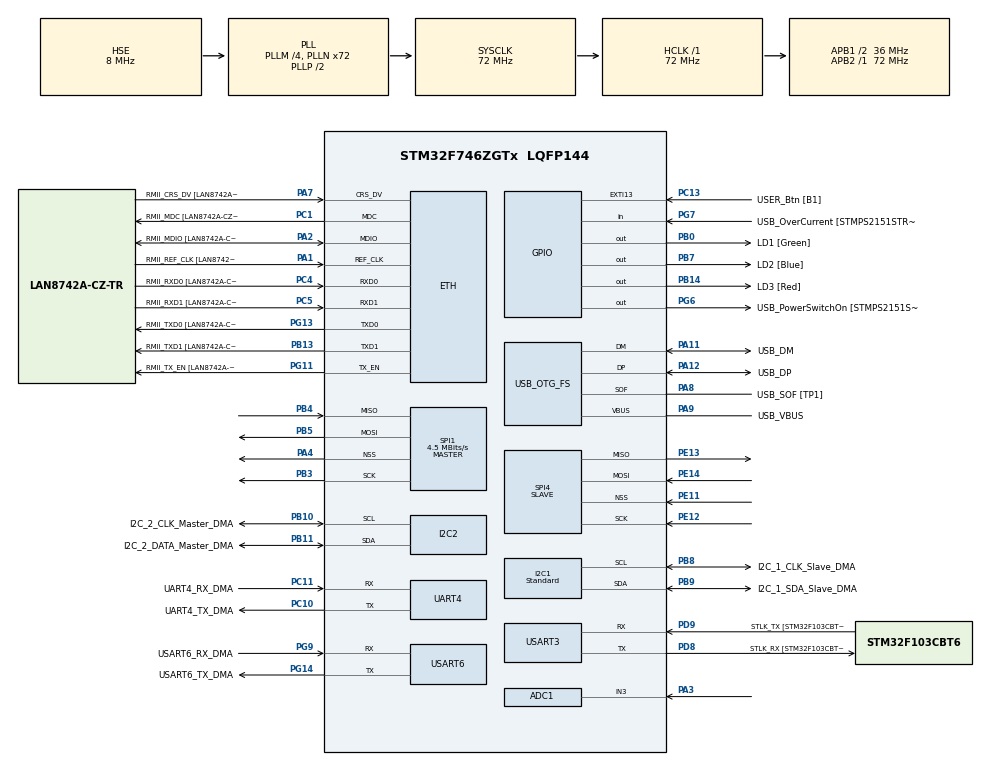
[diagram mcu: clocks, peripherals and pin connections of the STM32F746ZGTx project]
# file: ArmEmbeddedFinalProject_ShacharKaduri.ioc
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ADC1.Channel-0\#ChannelRegularConversion=ADC_CHANNEL_3
ADC1.ClockPrescaler=ADC_CLOCK_SYNC_PCLK_DIV8
ADC1.ContinuousConvMode=DISABLE
ADC1.DMAContinuousRequests=ENABLE
ADC1.InjNumberOfConversion=0
ADC1.NbrOfConversionFlag=1
ADC1.Rank-0\#ChannelRegularConversion=1
ADC1.SamplingTime-0\#ChannelRegularConversion=ADC_SAMPLETIME_84CYCLES
ADC1.master=1
Dma.ADC1.12.Direction=DMA_PERIPH_TO_MEMORY
Dma.ADC1.12.FIFOMode=DMA_FIFOMODE_DISABLE
Dma.ADC1.12.Instance=DMA2_Stream4
Dma.ADC1.12.MemDataAlignment=DMA_MDATAALIGN_HALFWORD
Dma.ADC1.12.MemInc=DMA_MINC_ENABLE
Dma.ADC1.12.Mode=DMA_CIRCULAR
Dma.ADC1.12.PeriphDataAlignment=DMA_PDATAALIGN_HALFWORD
Dma.ADC1.12.PeriphInc=DMA_PINC_DISABLE
Dma.ADC1.12.Priority=DMA_PRIORITY_LOW
Dma.I2C1_RX.6.Direction=DMA_PERIPH_TO_MEMORY
Dma.I2C1_RX.6.FIFOMode=DMA_FIFOMODE_DISABLE
Dma.I2C1_RX.6.Instance=DMA1_Stream5
Dma.I2C1_RX.6.MemDataAlignment=DMA_MDATAALIGN_BYTE
Dma.I2C1_RX.6.MemInc=DMA_MINC_ENABLE
Dma.I2C1_RX.6.Mode=DMA_NORMAL
Dma.I2C1_RX.6.PeriphDataAlignment=DMA_PDATAALIGN_BYTE
Dma.I2C1_RX.6.PeriphInc=DMA_PINC_DISABLE
Dma.I2C1_RX.6.Priority=DMA_PRIORITY_LOW
Dma.I2C1_TX.7.Direction=DMA_MEMORY_TO_PERIPH
Dma.I2C1_TX.7.FIFOMode=DMA_FIFOMODE_DISABLE
Dma.I2C1_TX.7.Instance=DMA1_Stream6
Dma.I2C1_TX.7.MemDataAlignment=DMA_MDATAALIGN_BYTE
Dma.I2C1_TX.7.MemInc=DMA_MINC_ENABLE
Dma.I2C1_TX.7.Mode=DMA_NORMAL
Dma.I2C1_TX.7.PeriphDataAlignment=DMA_PDATAALIGN_BYTE
Dma.I2C1_TX.7.PeriphInc=DMA_PINC_DISABLE
Dma.I2C1_TX.7.Priority=DMA_PRIORITY_LOW
Dma.I2C2_RX.4.Direction=DMA_PERIPH_TO_MEMORY
Dma.I2C2_RX.4.FIFOMode=DMA_FIFOMODE_DISABLE
Dma.I2C2_RX.4.Instance=DMA1_Stream3
Dma.I2C2_RX.4.MemDataAlignment=DMA_MDATAALIGN_BYTE
Dma.I2C2_RX.4.MemInc=DMA_MINC_ENABLE
Dma.I2C2_RX.4.Mode=DMA_NORMAL
Dma.I2C2_RX.4.PeriphDataAlignment=DMA_PDATAALIGN_BYTE
Dma.I2C2_RX.4.PeriphInc=DMA_PINC_DISABLE
Dma.I2C2_RX.4.Priority=DMA_PRIORITY_LOW
Dma.I2C2_TX.5.Direction=DMA_MEMORY_TO_PERIPH
Dma.I2C2_TX.5.FIFOMode=DMA_FIFOMODE_DISABLE
Dma.I2C2_TX.5.Instance=DMA1_Stream7
Dma.I2C2_TX.5.MemDataAlignment=DMA_MDATAALIGN_BYTE
Dma.I2C2_TX.5.MemInc=DMA_MINC_ENABLE
Dma.I2C2_TX.5.Mode=DMA_NORMAL
Dma.I2C2_TX.5.PeriphDataAlignment=DMA_PDATAALIGN_BYTE
Dma.I2C2_TX.5.PeriphInc=DMA_PINC_DISABLE
Dma.I2C2_TX.5.Priority=DMA_PRIORITY_LOW
Dma.Request0=UART4_RX
Dma.Request1=UART4_TX
Dma.Request10=SPI1_RX
Dma.Request11=SPI1_TX
Dma.Request12=ADC1
Dma.Request2=USART6_RX
Dma.Request3=USART6_TX
Dma.Request4=I2C2_RX
Dma.Request5=I2C2_TX
Dma.Request6=I2C1_RX
Dma.Request7=I2C1_TX
Dma.Request8=SPI4_RX
Dma.Request9=SPI4_TX
Dma.SPI1_RX.10.Direction=DMA_PERIPH_TO_MEMORY
Dma.SPI1_RX.10.FIFOMode=DMA_FIFOMODE_DISABLE
Dma.SPI1_RX.10.Instance=DMA2_Stream0
Dma.SPI1_RX.10.MemDataAlignment=DMA_MDATAALIGN_BYTE
Dma.SPI1_RX.10.MemInc=DMA_MINC_ENABLE
Dma.SPI1_RX.10.Mode=DMA_NORMAL
Dma.SPI1_RX.10.PeriphDataAlignment=DMA_PDATAALIGN_BYTE
Dma.SPI1_RX.10.PeriphInc=DMA_PINC_DISABLE
Dma.SPI1_RX.10.Priority=DMA_PRIORITY_LOW
Dma.SPI1_TX.11.Direction=DMA_MEMORY_TO_PERIPH
Dma.SPI1_TX.11.FIFOMode=DMA_FIFOMODE_DISABLE
Dma.SPI1_TX.11.Instance=DMA2_Stream5
Dma.SPI1_TX.11.MemDataAlignment=DMA_MDATAALIGN_BYTE
Dma.SPI1_TX.11.MemInc=DMA_MINC_ENABLE
Dma.SPI1_TX.11.Mode=DMA_NORMAL
Dma.SPI1_TX.11.PeriphDataAlignment=DMA_PDATAALIGN_BYTE
Dma.SPI1_TX.11.PeriphInc=DMA_PINC_DISABLE
Dma.SPI1_TX.11.Priority=DMA_PRIORITY_LOW
Dma.SPI4_RX.8.Direction=DMA_PERIPH_TO_MEMORY
Dma.SPI4_RX.8.FIFOMode=DMA_FIFOMODE_DISABLE
Dma.SPI4_RX.8.Instance=DMA2_Stream3
Dma.SPI4_RX.8.MemDataAlignment=DMA_MDATAALIGN_BYTE
Dma.SPI4_RX.8.MemInc=DMA_MINC_ENABLE
Dma.SPI4_RX.8.Mode=DMA_NORMAL
Dma.SPI4_RX.8.PeriphDataAlignment=DMA_PDATAALIGN_BYTE
Dma.SPI4_RX.8.PeriphInc=DMA_PINC_DISABLE
Dma.SPI4_RX.8.Priority=DMA_PRIORITY_LOW
Dma.SPI4_TX.9.Direction=DMA_MEMORY_TO_PERIPH
Dma.SPI4_TX.9.FIFOMode=DMA_FIFOMODE_DISABLE
Dma.SPI4_TX.9.Instance=DMA2_Stream1
Dma.SPI4_TX.9.MemDataAlignment=DMA_MDATAALIGN_BYTE
Dma.SPI4_TX.9.MemInc=DMA_MINC_ENABLE
Dma.SPI4_TX.9.Mode=DMA_NORMAL
Dma.SPI4_TX.9.PeriphDataAlignment=DMA_PDATAALIGN_BYTE
Dma.SPI4_TX.9.PeriphInc=DMA_PINC_DISABLE
Dma.SPI4_TX.9.Priority=DMA_PRIORITY_LOW
Dma.UART4_RX.0.Direction=DMA_PERIPH_TO_MEMORY
Dma.UART4_RX.0.FIFOMode=DMA_FIFOMODE_DISABLE
Dma.UART4_RX.0.Instance=DMA1_Stream2
Dma.UART4_RX.0.MemDataAlignment=DMA_MDATAALIGN_BYTE
Dma.UART4_RX.0.MemInc=DMA_MINC_ENABLE
Dma.UART4_RX.0.Mode=DMA_NORMAL
Dma.UART4_RX.0.PeriphDataAlignment=DMA_PDATAALIGN_BYTE
Dma.UART4_RX.0.PeriphInc=DMA_PINC_DISABLE
Dma.UART4_RX.0.Priority=DMA_PRIORITY_LOW
Dma.UART4_TX.1.Direction=DMA_MEMORY_TO_PERIPH
Dma.UART4_TX.1.FIFOMode=DMA_FIFOMODE_DISABLE
Dma.UART4_TX.1.Instance=DMA1_Stream4
Dma.UART4_TX.1.MemDataAlignment=DMA_MDATAALIGN_BYTE
Dma.UART4_TX.1.MemInc=DMA_MINC_ENABLE
Dma.UART4_TX.1.Mode=DMA_NORMAL
Dma.UART4_TX.1.PeriphDataAlignment=DMA_PDATAALIGN_BYTE
Dma.UART4_TX.1.PeriphInc=DMA_PINC_DISABLE
Dma.UART4_TX.1.Priority=DMA_PRIORITY_LOW
Dma.USART6_RX.2.Direction=DMA_PERIPH_TO_MEMORY
Dma.USART6_RX.2.FIFOMode=DMA_FIFOMODE_DISABLE
Dma.USART6_RX.2.Instance=DMA2_Stream2
Dma.USART6_RX.2.MemDataAlignment=DMA_MDATAALIGN_BYTE
Dma.USART6_RX.2.MemInc=DMA_MINC_ENABLE
Dma.USART6_RX.2.Mode=DMA_NORMAL
Dma.USART6_RX.2.PeriphDataAlignment=DMA_PDATAALIGN_BYTE
Dma.USART6_RX.2.PeriphInc=DMA_PINC_DISABLE
Dma.USART6_RX.2.Priority=DMA_PRIORITY_LOW
Dma.USART6_TX.3.Direction=DMA_MEMORY_TO_PERIPH
Dma.USART6_TX.3.FIFOMode=DMA_FIFOMODE_DISABLE
Dma.USART6_TX.3.Instance=DMA2_Stream6
Dma.USART6_TX.3.MemDataAlignment=DMA_MDATAALIGN_BYTE
Dma.USART6_TX.3.MemInc=DMA_MINC_ENABLE
Dma.USART6_TX.3.Mode=DMA_NORMAL
Dma.USART6_TX.3.PeriphDataAlignment=DMA_PDATAALIGN_BYTE
Dma.USART6_TX.3.PeriphInc=DMA_PINC_DISABLE
Dma.USART6_TX.3.Priority=DMA_PRIORITY_LOW
ETH.MediaInterface=HAL_ETH_RMII_MODE
ETH.PHY_Name=LAN8742A_PHY_ADDRESS
ETH.PHY_Value=0
ETH.PhyAddress=0
I2C1.AddressingMode=I2C_ADDRESSINGMODE_7BIT
I2C1.I2C_Speed_Mode=I2C_Standard
I2C1.OwnAddress=15
I2C1.Timing=0x10808DD3
I2C2.AddressingMode=I2C_ADDRESSINGMODE_7BIT
I2C2.Timing=0x10808DD3
LWIP.BSP.number=1
LWIP.IP_ADDRESS=192.168.001.002
LWIP.LWIP_DHCP=0
LWIP.NETMASK_ADDRESS=255.255.255.000
LWIP.Version=v2.1.2_Cube
LWIP0.BSP.STBoard=false
LWIP0.BSP.api=BSP_COMPONENT_DRIVER
LWIP0.BSP.component=LAN8742
LWIP0.BSP.instance=LAN8742
LWIP0.BSP.name=Driver_PHY
LWIP0.BSP.semaphore=S_LAN8742
LWIP0.BSP.solution=LAN8742
Mcu.Family=STM32F7
Mcu.Name=STM32F746ZGTx
Mcu.Package=LQFP144
NVIC.ADC_IRQn=true\:0\:0\:false\:false\:true\:true\:true\:true
NVIC.DMA1_Stream2_IRQn=true\:0\:0\:false\:false\:true\:false\:true\:true
NVIC.DMA1_Stream3_IRQn=true\:0\:0\:false\:false\:true\:false\:true\:true
NVIC.DMA1_Stream4_IRQn=true\:0\:0\:false\:false\:true\:false\:true\:true
NVIC.DMA1_Stream5_IRQn=true\:0\:0\:false\:false\:true\:false\:true\:true
NVIC.DMA1_Stream6_IRQn=true\:0\:0\:false\:false\:true\:false\:true\:true
NVIC.DMA1_Stream7_IRQn=true\:0\:0\:false\:false\:true\:false\:true\:true
NVIC.DMA2_Stream0_IRQn=true\:0\:0\:false\:false\:true\:false\:true\:true
NVIC.DMA2_Stream1_IRQn=true\:0\:0\:false\:false\:true\:false\:true\:true
NVIC.DMA2_Stream2_IRQn=true\:0\:0\:false\:false\:true\:false\:true\:true
NVIC.DMA2_Stream3_IRQn=true\:0\:0\:false\:false\:true\:false\:true\:true
NVIC.DMA2_Stream4_IRQn=true\:0\:0\:false\:false\:true\:false\:true\:true
NVIC.DMA2_Stream5_IRQn=true\:0\:0\:false\:false\:true\:false\:true\:true
NVIC.DMA2_Stream6_IRQn=true\:0\:0\:false\:false\:true\:false\:true\:true
NVIC.I2C1_ER_IRQn=true\:0\:0\:false\:false\:true\:true\:true\:true
NVIC.I2C1_EV_IRQn=true\:0\:0\:false\:false\:true\:true\:true\:true
NVIC.I2C2_ER_IRQn=true\:0\:0\:false\:false\:true\:true\:true\:true
NVIC.I2C2_EV_IRQn=true\:0\:0\:false\:false\:true\:true\:true\:true
NVIC.PriorityGroup=NVIC_PRIORITYGROUP_4
NVIC.SPI1_IRQn=true\:0\:0\:false\:false\:true\:true\:true\:true
NVIC.SPI4_IRQn=true\:0\:0\:false\:false\:true\:true\:true\:true
NVIC.TIM3_IRQn=true\:0\:0\:false\:false\:true\:true\:true\:true
NVIC.UART4_IRQn=true\:0\:0\:false\:false\:true\:true\:true\:true
NVIC.USART6_IRQn=true\:0\:0\:false\:false\:true\:true\:true\:true
PA1.GPIO_Label=RMII_REF_CLK [LAN8742A-CZ-TR_REFCLK0]
PA1.Mode=RMII
PA1.Signal=ETH_REF_CLK
PA10.GPIO_Label=USB_ID
PA10.Signal=USB_OTG_FS_ID
PA11.GPIO_Label=USB_DM
PA11.Mode=Device_Only
PA11.Signal=USB_OTG_FS_DM
PA12.GPIO_Label=USB_DP
PA12.Mode=Device_Only
PA12.Signal=USB_OTG_FS_DP
PA13.GPIO_Label=TMS
PA13.Mode=Serial_Wire
PA13.Signal=SYS_JTMS-SWDIO
PA14.GPIO_Label=TCK
PA14.Mode=Serial_Wire
PA14.Signal=SYS_JTCK-SWCLK
PA2.GPIO_Label=RMII_MDIO [LAN8742A-CZ-TR_MDIO]
PA2.Mode=RMII
PA2.Signal=ETH_MDIO
PA3.Signal=ADCx_IN3
PA4.Mode=NSS_Signal_Hard_Output
PA4.Signal=SPI1_NSS
PA7.GPIO_Label=RMII_CRS_DV [LAN8742A-CZ-TR_CRS_DV]
PA7.Mode=RMII
PA7.Signal=ETH_CRS_DV
PA8.GPIO_Label=USB_SOF [TP1]
PA8.Mode=Activate_SOF_FS
PA8.Signal=USB_OTG_FS_SOF
PA9.GPIO_Label=USB_VBUS
PA9.Mode=Activate_VBUS
PA9.Signal=USB_OTG_FS_VBUS
PB0.GPIO_Label=LD1 [Green]
PB0.Signal=GPIO_Output
PB10.GPIO_Label=I2C_2_CLK_Master_DMA
PB10.GPIO_Pu=GPIO_PULLUP
PB10.Mode=I2C
PB10.Signal=I2C2_SCL
PB11.GPIO_Label=I2C_2_DATA_Master_DMA
PB11.GPIO_Pu=GPIO_PULLUP
PB11.Mode=I2C
PB11.Signal=I2C2_SDA
PB13.GPIO_Label=RMII_TXD1 [LAN8742A-CZ-TR_TXD1]
PB13.Mode=RMII
PB13.Signal=ETH_TXD1
PB14.GPIO_Label=LD3 [Red]
PB14.Signal=GPIO_Output
PB15.Signal=SPI2_MOSI
PB3.Mode=Full_Duplex_Master
PB3.Signal=SPI1_SCK
PB4.Mode=Full_Duplex_Master
PB4.Signal=SPI1_MISO
PB5.Mode=Full_Duplex_Master
PB5.Signal=SPI1_MOSI
PB7.GPIO_Label=LD2 [Blue]
PB7.Signal=GPIO_Output
PB8.GPIO_Label=I2C_1_CLK_Slave_DMA
PB8.GPIO_Mode=GPIO_MODE_AF_OD
PB8.GPIO_Pu=GPIO_PULLUP
PB8.GPIO_Speed=GPIO_SPEED_FREQ_VERY_HIGH
PB8.Mode=I2C
PB8.Signal=I2C1_SCL
PB9.GPIO_Label=I2C_1_SDA_Slave_DMA
PB9.GPIO_Mode=GPIO_MODE_AF_OD
PB9.GPIO_Pu=GPIO_PULLUP
PB9.GPIO_Speed=GPIO_SPEED_FREQ_VERY_HIGH
PB9.Mode=I2C
PB9.Signal=I2C1_SDA
PC1.GPIO_Label=RMII_MDC [LAN8742A-CZ-TR_MDC]
PC1.Mode=RMII
PC1.Signal=ETH_MDC
PC10.GPIO_Label=UART4_TX_DMA
PC10.GPIO_PuPd=GPIO_PULLUP
PC10.Mode=Asynchronous
PC10.Signal=UART4_TX
PC11.GPIO_Label=UART4_RX_DMA
PC11.GPIO_PuPd=GPIO_PULLUP
PC11.Mode=Asynchronous
PC11.Signal=UART4_RX
PC13.GPIO_Label=USER_Btn [B1]
PC13.Signal=GPXTI13
PC14/OSC32_IN.Signal=RCC_OSC32_IN
PC15/OSC32_OUT.Signal=RCC_OSC32_OUT
PC4.GPIO_Label=RMII_RXD0 [LAN8742A-CZ-TR_RXD0]
PC4.Mode=RMII
PC4.Signal=ETH_RXD0
PC5.GPIO_Label=RMII_RXD1 [LAN8742A-CZ-TR_RXD1]
PC5.Mode=RMII
PC5.Signal=ETH_RXD1
PD8.GPIO_Label=STLK_RX [STM32F103CBT6_PA3]
PD8.Mode=Asynchronous
PD8.Signal=USART3_TX
PD9.GPIO_Label=STLK_TX [STM32F103CBT6_PA2]
PD9.Mode=Asynchronous
PD9.Signal=USART3_RX
PE11.Mode=NSS_Signal_Hard_Input
PE11.Signal=SPI4_NSS
PE12.Mode=Full_Duplex_Slave
PE12.Signal=SPI4_SCK
PE13.Mode=Full_Duplex_Slave
PE13.Signal=SPI4_MISO
PE14.Mode=Full_Duplex_Slave
PE14.Signal=SPI4_MOSI
PG11.GPIO_Label=RMII_TX_EN [LAN8742A-CZ-TR_TXEN]
PG11.Mode=RMII
PG11.Signal=ETH_TX_EN
PG13.GPIO_Label=RMII_TXD0 [LAN8742A-CZ-TR_TXD0]
PG13.Mode=RMII
PG13.Signal=ETH_TXD0
PG14.GPIO_Label=USART6_TX_DMA
PG14.GPIO_PuPd=GPIO_PULLUP
PG14.Mode=Asynchronous
PG14.Signal=USART6_TX
PG6.GPIO_Label=USB_PowerSwitchOn [STMPS2151STR_EN]
PG6.Signal=GPIO_Output
PG7.GPIO_Label=USB_OverCurrent [STMPS2151STR_FAULT]
PG7.Signal=GPIO_Input
PG9.GPIO_Label=USART6_RX_DMA
PG9.GPIO_PuPd=GPIO_PULLUP
PG9.Mode=Asynchronous
PG9.Signal=USART6_RX
PH0/OSC_IN.GPIO_Label=MCO [STM32F103CBT6_PA8]
PH0/OSC_IN.Mode=HSE-External-Oscillator
PH0/OSC_IN.Signal=RCC_OSC_IN
PH1/OSC_OUT.Mode=HSE-External-Oscillator
PH1/OSC_OUT.Signal=RCC_OSC_OUT
ProjectManager.HeapSize=0x200
ProjectManager.StackSize=0x400
ProjectManager.TargetToolchain=STM32CubeIDE
RCC.48MHZClocksFreq_Value=24000000
RCC.AHBFreq_Value=72000000
RCC.APB1CLKDivider=RCC_HCLK_DIV2
RCC.APB1Freq_Value=36000000
RCC.APB1TimFreq_Value=72000000
RCC.APB2Freq_Value=72000000
RCC.APB2TimFreq_Value=72000000
RCC.CortexFreq_Value=72000000
RCC.HCLKFreq_Value=72000000
RCC.HSE_VALUE=8000000
RCC.HSI_VALUE=16000000
RCC.I2C1CLockSelection=RCC_I2C1CLKSOURCE_SYSCLK
RCC.I2C2CLockSelection=RCC_I2C2CLKSOURCE_SYSCLK
RCC.PLLM=4
RCC.PLLMUL=RCC_PLL_MUL9
RCC.PLLN=72
RCC.PLLQ=3
RCC.PRESCALERUSB=RCC_USBCLKSOURCE_PLL_DIV1_5
RCC.SYSCLKFreq_VALUE=72000000
RCC.SYSCLKSource=RCC_SYSCLKSOURCE_PLLCLK
RCC.SYSCLKSourceVirtual=RCC_SYSCLKSOURCE_PLLCLK
RCC.UART4CLockSelection=RCC_UART4CLKSOURCE_SYSCLK
RCC.USBFreq_Value=48000000
RCC.VCOOutputFreq_Value=144000000
SH.ADCx_IN3.0=ADC1_IN3,IN3
SPI1.BaudRatePrescaler=SPI_BAUDRATEPRESCALER_16
SPI1.CalculateBaudRate=4.5 MBits/s
SPI1.DataSize=SPI_DATASIZE_8BIT
SPI1.Direction=SPI_DIRECTION_2LINES
SPI1.Mode=SPI_MODE_MASTER
SPI1.VirtualNSS=VM_NSSHARD
SPI1.VirtualType=VM_MASTER
SPI4.DataSize=SPI_DATASIZE_8BIT
SPI4.Direction=SPI_DIRECTION_2LINES
SPI4.Mode=SPI_MODE_SLAVE
SPI4.VirtualNSS=VM_NSSHARD
SPI4.VirtualType=VM_SLAVE
TIM3.AutoReloadPreload=TIM_AUTORELOAD_PRELOAD_ENABLE
TIM3.Period=10000-1
TIM3.Prescaler=7200-1
USART3.VirtualMode-Asynchronous=VM_ASYNC
USART6.VirtualMode-Asynchronous=VM_ASYNC
USB_OTG_FS.VirtualMode=Device_Only
VP_LWIP_VS_Enabled.Mode=Enabled
VP_TIM3_VS_ClockSourceINT.Mode=Internal
board=NUCLEO-F746ZG

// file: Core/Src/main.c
/* USER CODE BEGIN Header */
/**
  ******************************************************************************
  * @file           : main.c
  * @brief          : Main program body
  ******************************************************************************
  * @attention
  *
  * Copyright (c) 2022 STMicroelectronics.
  * All rights reserved.
  *
  * This software is licensed under terms that can be found in the LICENSE file
  * in the root directory of this software component.
  * If no LICENSE file comes with this software, it is provided AS-IS.
  *
  ******************************************************************************
  */
/* USER CODE END Header */
#include "main.h"
#include "lwip.h"

/* USER CODE BEGIN Includes */
#include "../../UUT/Inc/MAIN_UUT.h"
/* USER CODE END Includes */

ADC_HandleTypeDef hadc1;
DMA_HandleTypeDef hdma_adc1;

I2C_HandleTypeDef hi2c1;
I2C_HandleTypeDef hi2c2;
DMA_HandleTypeDef hdma_i2c1_rx;
DMA_HandleTypeDef hdma_i2c1_tx;
DMA_HandleTypeDef hdma_i2c2_rx;
DMA_HandleTypeDef hdma_i2c2_tx;

SPI_HandleTypeDef hspi1;
SPI_HandleTypeDef hspi4;
DMA_HandleTypeDef hdma_spi1_rx;
DMA_HandleTypeDef hdma_spi1_tx;
DMA_HandleTypeDef hdma_spi4_rx;
DMA_HandleTypeDef hdma_spi4_tx;

TIM_HandleTypeDef htim3;

UART_HandleTypeDef huart4;
UART_HandleTypeDef huart3;
UART_HandleTypeDef huart6;
DMA_HandleTypeDef hdma_uart4_rx;
DMA_HandleTypeDef hdma_uart4_tx;
DMA_HandleTypeDef hdma_usart6_rx;
DMA_HandleTypeDef hdma_usart6_tx;

PCD_HandleTypeDef hpcd_USB_OTG_FS;

void SystemClock_Config(void);
static void MX_GPIO_Init(void);
static void MX_USART3_UART_Init(void);
static void MX_USB_OTG_FS_PCD_Init(void);
static void MX_UART4_Init(void);
static void MX_DMA_Init(void);
static void MX_I2C1_Init(void);
static void MX_I2C2_Init(void);
static void MX_USART6_UART_Init(void);
static void MX_SPI4_Init(void);
static void MX_SPI1_Init(void);
static void MX_ADC1_Init(void);
static void MX_TIM3_Init(void);

int main(void)
{

  /* MCU Configuration--------------------------------------------------------*/

  /* Reset of all peripherals, Initializes the Flash interface and the Systick. */
  HAL_Init();

  /* Configure the system clock */
  SystemClock_Config();

  /* USER CODE BEGIN SysInit */
  MX_DMA_Init();
  /* USER CODE END SysInit */

  /* Initialize all configured peripherals */
  MX_GPIO_Init();
  MX_USART3_UART_Init();
  MX_USB_OTG_FS_PCD_Init();
  MX_LWIP_Init();
  MX_UART4_Init();
  MX_DMA_Init();
  MX_I2C1_Init();
  MX_I2C2_Init();
  MX_USART6_UART_Init();
  MX_SPI4_Init();
  MX_SPI1_Init();
  MX_ADC1_Init();
  MX_TIM3_Init();
  /* USER CODE BEGIN 2 */
  UUT_main();
  /* USER CODE END 2 */

  /* Infinite loop */
  while (1)
  {

  }
}

void SystemClock_Config(void)
{
  RCC_OscInitTypeDef RCC_OscInitStruct = {0};
  RCC_ClkInitTypeDef RCC_ClkInitStruct = {0};

  /** Configure the main internal regulator output voltage
  */
  __HAL_RCC_PWR_CLK_ENABLE();
  __HAL_PWR_VOLTAGESCALING_CONFIG(PWR_REGULATOR_VOLTAGE_SCALE3);

  /** Initializes the RCC Oscillators according to the specified parameters
  * in the RCC_OscInitTypeDef structure.
  */
  RCC_OscInitStruct.OscillatorType = RCC_OSCILLATORTYPE_HSE;
  RCC_OscInitStruct.HSEState = RCC_HSE_ON;
  RCC_OscInitStruct.PLL.PLLState = RCC_PLL_ON;
  RCC_OscInitStruct.PLL.PLLSource = RCC_PLLSOURCE_HSE;
  RCC_OscInitStruct.PLL.PLLM = 4;
  RCC_OscInitStruct.PLL.PLLN = 72;
  RCC_OscInitStruct.PLL.PLLP = RCC_PLLP_DIV2;
  RCC_OscInitStruct.PLL.PLLQ = 3;
  if (HAL_RCC_OscConfig(&RCC_OscInitStruct) != HAL_OK)
  {
    Error_Handler();
  }

  /** Initializes the CPU, AHB and APB buses clocks
  */
  RCC_ClkInitStruct.ClockType = RCC_CLOCKTYPE_HCLK|RCC_CLOCKTYPE_SYSCLK
                              |RCC_CLOCKTYPE_PCLK1|RCC_CLOCKTYPE_PCLK2;
  RCC_ClkInitStruct.SYSCLKSource = RCC_SYSCLKSOURCE_PLLCLK;
  RCC_ClkInitStruct.AHBCLKDivider = RCC_SYSCLK_DIV1;
  RCC_ClkInitStruct.APB1CLKDivider = RCC_HCLK_DIV2;
  RCC_ClkInitStruct.APB2CLKDivider = RCC_HCLK_DIV1;

  if (HAL_RCC_ClockConfig(&RCC_ClkInitStruct, FLASH_LATENCY_2) != HAL_OK)
  {
    Error_Handler();
  }
}

static void MX_ADC1_Init(void)
{

  ADC_ChannelConfTypeDef sConfig = {0};

  /** Configure the global features of the ADC (Clock, Resolution, Data Alignment and number of conversion)
  */
  hadc1.Instance = ADC1;
  hadc1.Init.ClockPrescaler = ADC_CLOCK_SYNC_PCLK_DIV8;
  hadc1.Init.Resolution = ADC_RESOLUTION_12B;
  hadc1.Init.ScanConvMode = ADC_SCAN_DISABLE;
  hadc1.Init.ContinuousConvMode = DISABLE;
  hadc1.Init.DiscontinuousConvMode = DISABLE;
  hadc1.Init.ExternalTrigConvEdge = ADC_EXTERNALTRIGCONVEDGE_NONE;
  hadc1.Init.ExternalTrigConv = ADC_SOFTWARE_START;
  hadc1.Init.DataAlign = ADC_DATAALIGN_RIGHT;
  hadc1.Init.NbrOfConversion = 1;
  hadc1.Init.DMAContinuousRequests = ENABLE;
  hadc1.Init.EOCSelection = ADC_EOC_SINGLE_CONV;
  if (HAL_ADC_Init(&hadc1) != HAL_OK)
  {
    Error_Handler();
  }

  /** Configure for the selected ADC regular channel its corresponding rank in the sequencer and its sample time.
  */
  sConfig.Channel = ADC_CHANNEL_3;
  sConfig.Rank = ADC_REGULAR_RANK_1;
  sConfig.SamplingTime = ADC_SAMPLETIME_84CYCLES;
  if (HAL_ADC_ConfigChannel(&hadc1, &sConfig) != HAL_OK)
  {
    Error_Handler();
  }

}

static void MX_I2C1_Init(void)
{

  hi2c1.Instance = I2C1;
  hi2c1.Init.Timing = 0x10808DD3;
  hi2c1.Init.OwnAddress1 = 30;
  hi2c1.Init.AddressingMode = I2C_ADDRESSINGMODE_7BIT;
  hi2c1.Init.DualAddressMode = I2C_DUALADDRESS_DISABLE;
  hi2c1.Init.OwnAddress2 = 0;
  hi2c1.Init.OwnAddress2Masks = I2C_OA2_NOMASK;
  hi2c1.Init.GeneralCallMode = I2C_GENERALCALL_DISABLE;
  hi2c1.Init.NoStretchMode = I2C_NOSTRETCH_DISABLE;
  if (HAL_I2C_Init(&hi2c1) != HAL_OK)
  {
    Error_Handler();
  }

  /** Configure Analogue filter
  */
  if (HAL_I2CEx_ConfigAnalogFilter(&hi2c1, I2C_ANALOGFILTER_ENABLE) != HAL_OK)
  {
    Error_Handler();
  }

  /** Configure Digital filter
  */
  if (HAL_I2CEx_ConfigDigitalFilter(&hi2c1, 0) != HAL_OK)
  {
    Error_Handler();
  }

}

static void MX_I2C2_Init(void)
{

  hi2c2.Instance = I2C2;
  hi2c2.Init.Timing = 0x10808DD3;
  hi2c2.Init.OwnAddress1 = 0;
  hi2c2.Init.AddressingMode = I2C_ADDRESSINGMODE_7BIT;
  hi2c2.Init.DualAddressMode = I2C_DUALADDRESS_DISABLE;
  hi2c2.Init.OwnAddress2 = 0;
  hi2c2.Init.OwnAddress2Masks = I2C_OA2_NOMASK;
  hi2c2.Init.GeneralCallMode = I2C_GENERALCALL_DISABLE;
  hi2c2.Init.NoStretchMode = I2C_NOSTRETCH_DISABLE;
  if (HAL_I2C_Init(&hi2c2) != HAL_OK)
  {
    Error_Handler();
  }

  /** Configure Analogue filter
  */
  if (HAL_I2CEx_ConfigAnalogFilter(&hi2c2, I2C_ANALOGFILTER_ENABLE) != HAL_OK)
  {
    Error_Handler();
  }

  /** Configure Digital filter
  */
  if (HAL_I2CEx_ConfigDigitalFilter(&hi2c2, 0) != HAL_OK)
  {
    Error_Handler();
  }

}

static void MX_SPI1_Init(void)
{

  /* SPI1 parameter configuration*/
  hspi1.Instance = SPI1;
  hspi1.Init.Mode = SPI_MODE_MASTER;
  hspi1.Init.Direction = SPI_DIRECTION_2LINES;
  hspi1.Init.DataSize = SPI_DATASIZE_8BIT;
  hspi1.Init.CLKPolarity = SPI_POLARITY_LOW;
  hspi1.Init.CLKPhase = SPI_PHASE_1EDGE;
  hspi1.Init.NSS = SPI_NSS_HARD_OUTPUT;
  hspi1.Init.BaudRatePrescaler = SPI_BAUDRATEPRESCALER_16;
  hspi1.Init.FirstBit = SPI_FIRSTBIT_MSB;
  hspi1.Init.TIMode = SPI_TIMODE_DISABLE;
  hspi1.Init.CRCCalculation = SPI_CRCCALCULATION_DISABLE;
  hspi1.Init.CRCPolynomial = 7;
  hspi1.Init.CRCLength = SPI_CRC_LENGTH_DATASIZE;
  hspi1.Init.NSSPMode = SPI_NSS_PULSE_ENABLE;
  if (HAL_SPI_Init(&hspi1) != HAL_OK)
  {
    Error_Handler();
  }

}

static void MX_SPI4_Init(void)
{

  /* SPI4 parameter configuration*/
  hspi4.Instance = SPI4;
  hspi4.Init.Mode = SPI_MODE_SLAVE;
  hspi4.Init.Direction = SPI_DIRECTION_2LINES;
  hspi4.Init.DataSize = SPI_DATASIZE_8BIT;
  hspi4.Init.CLKPolarity = SPI_POLARITY_LOW;
  hspi4.Init.CLKPhase = SPI_PHASE_1EDGE;
  hspi4.Init.NSS = SPI_NSS_HARD_INPUT;
  hspi4.Init.FirstBit = SPI_FIRSTBIT_MSB;
  hspi4.Init.TIMode = SPI_TIMODE_DISABLE;
  hspi4.Init.CRCCalculation = SPI_CRCCALCULATION_DISABLE;
  hspi4.Init.CRCPolynomial = 7;
  hspi4.Init.CRCLength = SPI_CRC_LENGTH_DATASIZE;
  hspi4.Init.NSSPMode = SPI_NSS_PULSE_DISABLE;
  if (HAL_SPI_Init(&hspi4) != HAL_OK)
  {
    Error_Handler();
  }

}

static void MX_TIM3_Init(void)
{

  TIM_ClockConfigTypeDef sClockSourceConfig = {0};
  TIM_MasterConfigTypeDef sMasterConfig = {0};

  htim3.Instance = TIM3;
  htim3.Init.Prescaler = 7200-1;
  htim3.Init.CounterMode = TIM_COUNTERMODE_UP;
  htim3.Init.Period = 10000-1;
  htim3.Init.ClockDivision = TIM_CLOCKDIVISION_DIV1;
  htim3.Init.AutoReloadPreload = TIM_AUTORELOAD_PRELOAD_ENABLE;
  if (HAL_TIM_Base_Init(&htim3) != HAL_OK)
  {
    Error_Handler();
  }
  sClockSourceConfig.ClockSource = TIM_CLOCKSOURCE_INTERNAL;
  if (HAL_TIM_ConfigClockSource(&htim3, &sClockSourceConfig) != HAL_OK)
  {
    Error_Handler();
  }
  sMasterConfig.MasterOutputTrigger = TIM_TRGO_RESET;
  sMasterConfig.MasterSlaveMode = TIM_MASTERSLAVEMODE_DISABLE;
  if (HAL_TIMEx_MasterConfigSynchronization(&htim3, &sMasterConfig) != HAL_OK)
  {
    Error_Handler();
  }

}

static void MX_UART4_Init(void)
{

  huart4.Instance = UART4;
  huart4.Init.BaudRate = 115200;
  huart4.Init.WordLength = UART_WORDLENGTH_8B;
  huart4.Init.StopBits = UART_STOPBITS_1;
  huart4.Init.Parity = UART_PARITY_NONE;
  huart4.Init.Mode = UART_MODE_TX_RX;
  huart4.Init.HwFlowCtl = UART_HWCONTROL_NONE;
  huart4.Init.OverSampling = UART_OVERSAMPLING_16;
  huart4.Init.OneBitSampling = UART_ONE_BIT_SAMPLE_DISABLE;
  huart4.AdvancedInit.AdvFeatureInit = UART_ADVFEATURE_NO_INIT;
  if (HAL_UART_Init(&huart4) != HAL_OK)
  {
    Error_Handler();
  }

}

static void MX_USART3_UART_Init(void)
{

  huart3.Instance = USART3;
  huart3.Init.BaudRate = 115200;
  huart3.Init.WordLength = UART_WORDLENGTH_8B;
  huart3.Init.StopBits = UART_STOPBITS_1;
  huart3.Init.Parity = UART_PARITY_NONE;
  huart3.Init.Mode = UART_MODE_TX_RX;
  huart3.Init.HwFlowCtl = UART_HWCONTROL_NONE;
  huart3.Init.OverSampling = UART_OVERSAMPLING_16;
  huart3.Init.OneBitSampling = UART_ONE_BIT_SAMPLE_DISABLE;
  huart3.AdvancedInit.AdvFeatureInit = UART_ADVFEATURE_NO_INIT;
  if (HAL_UART_Init(&huart3) != HAL_OK)
  {
    Error_Handler();
  }

}

static void MX_USART6_UART_Init(void)
{

  huart6.Instance = USART6;
  huart6.Init.BaudRate = 115200;
  huart6.Init.WordLength = UART_WORDLENGTH_8B;
  huart6.Init.StopBits = UART_STOPBITS_1;
  huart6.Init.Parity = UART_PARITY_NONE;
  huart6.Init.Mode = UART_MODE_TX_RX;
  huart6.Init.HwFlowCtl = UART_HWCONTROL_NONE;
  huart6.Init.OverSampling = UART_OVERSAMPLING_16;
  huart6.Init.OneBitSampling = UART_ONE_BIT_SAMPLE_DISABLE;
  huart6.AdvancedInit.AdvFeatureInit = UART_ADVFEATURE_NO_INIT;
  if (HAL_UART_Init(&huart6) != HAL_OK)
  {
    Error_Handler();
  }

}

static void MX_USB_OTG_FS_PCD_Init(void)
{

  hpcd_USB_OTG_FS.Instance = USB_OTG_FS;
  hpcd_USB_OTG_FS.Init.dev_endpoints = 6;
  hpcd_USB_OTG_FS.Init.speed = PCD_SPEED_FULL;
  hpcd_USB_OTG_FS.Init.dma_enable = DISABLE;
  hpcd_USB_OTG_FS.Init.phy_itface = PCD_PHY_EMBEDDED;
  hpcd_USB_OTG_FS.Init.Sof_enable = ENABLE;
  hpcd_USB_OTG_FS.Init.low_power_enable = DISABLE;
  hpcd_USB_OTG_FS.Init.lpm_enable = DISABLE;
  hpcd_USB_OTG_FS.Init.vbus_sensing_enable = ENABLE;
  hpcd_USB_OTG_FS.Init.use_dedicated_ep1 = DISABLE;
  if (HAL_PCD_Init(&hpcd_USB_OTG_FS) != HAL_OK)
  {
    Error_Handler();
  }

}

static void MX_DMA_Init(void)
{

  /* DMA controller clock enable */
  __HAL_RCC_DMA1_CLK_ENABLE();
  __HAL_RCC_DMA2_CLK_ENABLE();

  /* DMA interrupt init */
  /* DMA1_Stream2_IRQn interrupt configuration */
  HAL_NVIC_SetPriority(DMA1_Stream2_IRQn, 0, 0);
  HAL_NVIC_EnableIRQ(DMA1_Stream2_IRQn);
  /* DMA1_Stream3_IRQn interrupt configuration */
  HAL_NVIC_SetPriority(DMA1_Stream3_IRQn, 0, 0);
  HAL_NVIC_EnableIRQ(DMA1_Stream3_IRQn);
  /* DMA1_Stream4_IRQn interrupt configuration */
  HAL_NVIC_SetPriority(DMA1_Stream4_IRQn, 0, 0);
  HAL_NVIC_EnableIRQ(DMA1_Stream4_IRQn);
  /* DMA1_Stream5_IRQn interrupt configuration */
  HAL_NVIC_SetPriority(DMA1_Stream5_IRQn, 0, 0);
  HAL_NVIC_EnableIRQ(DMA1_Stream5_IRQn);
  /* DMA1_Stream6_IRQn interrupt configuration */
  HAL_NVIC_SetPriority(DMA1_Stream6_IRQn, 0, 0);
  HAL_NVIC_EnableIRQ(DMA1_Stream6_IRQn);
  /* DMA1_Stream7_IRQn interrupt configuration */
  HAL_NVIC_SetPriority(DMA1_Stream7_IRQn, 0, 0);
  HAL_NVIC_EnableIRQ(DMA1_Stream7_IRQn);
  /* DMA2_Stream0_IRQn interrupt configuration */
  HAL_NVIC_SetPriority(DMA2_Stream0_IRQn, 0, 0);
  HAL_NVIC_EnableIRQ(DMA2_Stream0_IRQn);
  /* DMA2_Stream1_IRQn interrupt configuration */
  HAL_NVIC_SetPriority(DMA2_Stream1_IRQn, 0, 0);
  HAL_NVIC_EnableIRQ(DMA2_Stream1_IRQn);
  /* DMA2_Stream2_IRQn interrupt configuration */
  HAL_NVIC_SetPriority(DMA2_Stream2_IRQn, 0, 0);
  HAL_NVIC_EnableIRQ(DMA2_Stream2_IRQn);
  /* DMA2_Stream3_IRQn interrupt configuration */
  HAL_NVIC_SetPriority(DMA2_Stream3_IRQn, 0, 0);
  HAL_NVIC_EnableIRQ(DMA2_Stream3_IRQn);
  /* DMA2_Stream4_IRQn interrupt configuration */
  HAL_NVIC_SetPriority(DMA2_Stream4_IRQn, 0, 0);
  HAL_NVIC_EnableIRQ(DMA2_Stream4_IRQn);
  /* DMA2_Stream5_IRQn interrupt configuration */
  HAL_NVIC_SetPriority(DMA2_Stream5_IRQn, 0, 0);
  HAL_NVIC_EnableIRQ(DMA2_Stream5_IRQn);
  /* DMA2_Stream6_IRQn interrupt configuration */
  HAL_NVIC_SetPriority(DMA2_Stream6_IRQn, 0, 0);
  HAL_NVIC_EnableIRQ(DMA2_Stream6_IRQn);

}

static void MX_GPIO_Init(void)
{
  GPIO_InitTypeDef GPIO_InitStruct = {0};

  /* GPIO Ports Clock Enable */
  __HAL_RCC_GPIOC_CLK_ENABLE();
  __HAL_RCC_GPIOH_CLK_ENABLE();
  __HAL_RCC_GPIOA_CLK_ENABLE();
  __HAL_RCC_GPIOB_CLK_ENABLE();
  __HAL_RCC_GPIOE_CLK_ENABLE();
  __HAL_RCC_GPIOD_CLK_ENABLE();
  __HAL_RCC_GPIOG_CLK_ENABLE();

  /*Configure GPIO pin Output Level */
  HAL_GPIO_WritePin(GPIOB, LD1_Pin|LD3_Pin|LD2_Pin, GPIO_PIN_RESET);

  /*Configure GPIO pin Output Level */
  HAL_GPIO_WritePin(USB_PowerSwitchOn_GPIO_Port, USB_PowerSwitchOn_Pin, GPIO_PIN_RESET);

  /*Configure GPIO pin : USER_Btn_Pin */
  GPIO_InitStruct.Pin = USER_Btn_Pin;
  GPIO_InitStruct.Mode = GPIO_MODE_IT_RISING;
  GPIO_InitStruct.Pull = GPIO_NOPULL;
  HAL_GPIO_Init(USER_Btn_GPIO_Port, &GPIO_InitStruct);

  /*Configure GPIO pins : LD1_Pin LD3_Pin LD2_Pin */
  GPIO_InitStruct.Pin = LD1_Pin|LD3_Pin|LD2_Pin;
  GPIO_InitStruct.Mode = GPIO_MODE_OUTPUT_PP;
  GPIO_InitStruct.Pull = GPIO_NOPULL;
  GPIO_InitStruct.Speed = GPIO_SPEED_FREQ_LOW;
  HAL_GPIO_Init(GPIOB, &GPIO_InitStruct);

  /*Configure GPIO pin : PB15 */
  GPIO_InitStruct.Pin = GPIO_PIN_15;
  GPIO_InitStruct.Mode = GPIO_MODE_AF_PP;
  GPIO_InitStruct.Pull = GPIO_NOPULL;
  GPIO_InitStruct.Speed = GPIO_SPEED_FREQ_VERY_HIGH;
  GPIO_InitStruct.Alternate = GPIO_AF5_SPI2;
  HAL_GPIO_Init(GPIOB, &GPIO_InitStruct);

  /*Configure GPIO pin : USB_PowerSwitchOn_Pin */
  GPIO_InitStruct.Pin = USB_PowerSwitchOn_Pin;
  GPIO_InitStruct.Mode = GPIO_MODE_OUTPUT_PP;
  GPIO_InitStruct.Pull = GPIO_NOPULL;
  GPIO_InitStruct.Speed = GPIO_SPEED_FREQ_LOW;
  HAL_GPIO_Init(USB_PowerSwitchOn_GPIO_Port, &GPIO_InitStruct);

  /*Configure GPIO pin : USB_OverCurrent_Pin */
  GPIO_InitStruct.Pin = USB_OverCurrent_Pin;
  GPIO_InitStruct.Mode = GPIO_MODE_INPUT;
  GPIO_InitStruct.Pull = GPIO_NOPULL;
  HAL_GPIO_Init(USB_OverCurrent_GPIO_Port, &GPIO_InitStruct);

}

void Error_Handler(void)
{
  __disable_irq();
  while (1)
  {
  }
}
